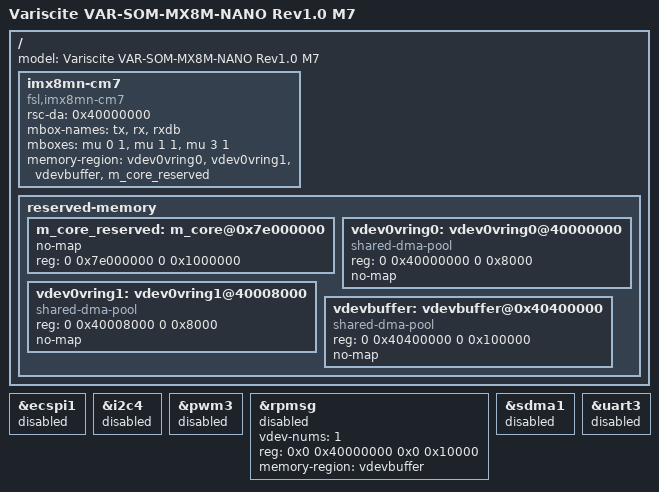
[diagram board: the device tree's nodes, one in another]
/*
 * Copyright 2018 NXP
 * Copyright 2019-2020 Variscite Ltd.
 *
 * This program is free software; you can redistribute it and/or
 * modify it under the terms of the GNU General Public License
 * as published by the Free Software Foundation; either version 2
 * of the License, or (at your option) any later version.
 *
 * This program is distributed in the hope that it will be useful,
 * but WITHOUT ANY WARRANTY; without even the implied warranty of
 * MERCHANTABILITY or FITNESS FOR A PARTICULAR PURPOSE.  See the
 * GNU General Public License for more details.
 */

#include "imx8mn-var-som-rev10-symphony.dts"

/ {
	model = "Variscite VAR-SOM-MX8M-NANO Rev1.0 M7";

	imx8mn-cm7 {
		compatible = "fsl,imx8mn-cm7";
		rsc-da = <0x40000000>;
		mbox-names = "tx", "rx", "rxdb";
		mboxes = <&mu 0 1
			  &mu 1 1
			  &mu 3 1>;
		memory-region = <&vdev0vring0>, <&vdev0vring1>, <&vdevbuffer>, <&m_core_reserved>;
		status = "okay";
	};
	
	reserved-memory {
		m_core_reserved: m_core@0x7e000000 {
			no-map;
			reg = <0 0x7e000000 0 0x1000000>;
		};

		vdev0vring0: vdev0vring0@40000000 {
			compatible = "shared-dma-pool";
			reg = <0 0x40000000 0 0x8000>;
			no-map;
		};

		vdev0vring1: vdev0vring1@40008000 {
			compatible = "shared-dma-pool";
			reg = <0 0x40008000 0 0x8000>;
			no-map;
		};
		vdevbuffer: vdevbuffer@0x40400000 {
			compatible = "shared-dma-pool";
			reg = <0 0x40400000 0 0x100000>;
			no-map;
		};
	};
};

/*
 * ATTENTION: M7 may use IPs like below
 * ECSPI1, GPIO4, GPT1, I2C4, WDOG1, PWM3, SDMA1/3, UART3
 */

&ecspi1 {
	status = "disabled";
};

&i2c4 {
	status = "disabled";
};

&pwm3 {
	status = "disabled";
};

&rpmsg{
	/*
	 * 64K for one rpmsg instance:
	 * --0x40000000~0x4000ffff: pingpong
	 */
	vdev-nums = <1>;
	reg = <0x0 0x40000000 0x0 0x10000>;
	memory-region = <&vdevbuffer>;
	status = "disabled";
};

&sdma1{
	status = "disabled";
};

&uart3 {
	status = "disabled";
};
